# PY32F403xx register map
Vendor: PUYA Co.Ltd; Series: ARMCM4; File version: 1.2
CPU: CM4 r0p1, little endian, MPU, FPU, 4 interrupt priority bits
Registers are 32-bit, read-write, reset 0x0 unless marked. A register's access mark holds for its fields unless they carry their own. Offsets are from the block's base; [hi:lo] are bit positions; {n}, {i} and the like mark numbered series.

## TIM6 — desc TIM
Base 0x40001000
Same registers: TIM7 0x40001400
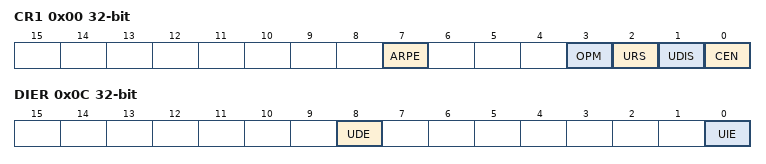
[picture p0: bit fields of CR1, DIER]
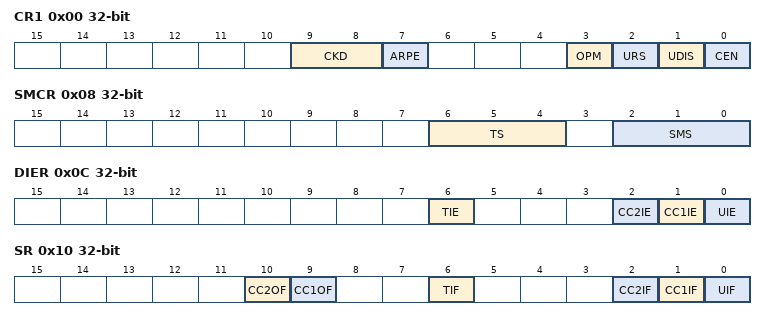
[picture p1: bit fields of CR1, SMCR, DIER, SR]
0x00 CR1
  [7] ARPE, [3] OPM, [2] URS, [1] UDIS, [0] CEN
0x04 CR2
  [6:4] MMS
    1=0; 2=1; 4=2
0x0C DIER
  [8] UDE, [0] UIE
0x10 SR
  [0] UIF
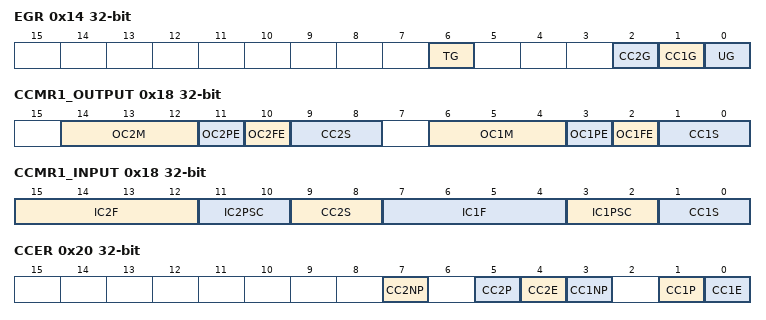
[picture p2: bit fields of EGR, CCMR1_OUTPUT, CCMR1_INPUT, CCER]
0x14 EGR
  [0] UG
0x24 CNT
  [15:0] CNT
0x28 PSC
  [15:0] PSC
0x2C ARR
  [15:0] ARR

## TIM9 — desc TIM
Base 0x40014C00
Same registers: TIM12 0x40001800
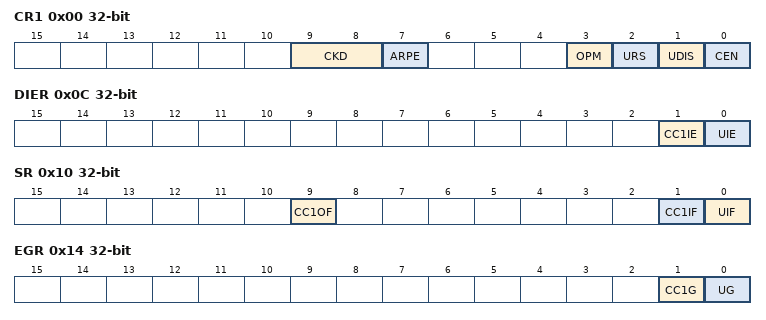
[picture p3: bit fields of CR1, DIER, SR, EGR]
0x00 CR1
  [9:8] CKD
    1=0; 2=1
  [7] ARPE
  [3] OPM
  [2] URS
  [1] UDIS
  [0] CEN
0x08 SMCR
  [6:4] TS
    1=0; 2=1; 4=2
  [2:0] SMS
    1=0; 2=1; 4=2
0x0C DIER
  [6] TIE, [2] CC2IE, [1] CC1IE, [0] UIE
0x10 SR
  [10] CC2OF, [9] CC1OF, [6] TIF, [2] CC2IF, [1] CC1IF, [0] UIF
0x14 EGR
  [6] TG, [2] CC2G, [1] CC1G, [0] UG
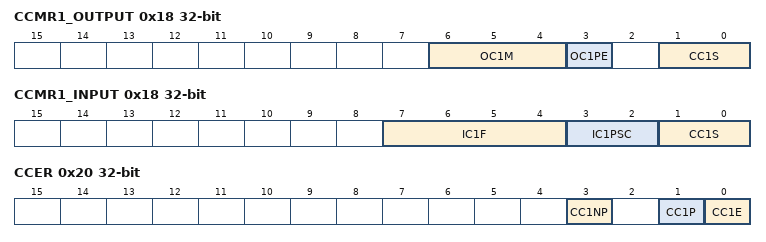
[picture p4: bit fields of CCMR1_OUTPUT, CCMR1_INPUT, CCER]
0x18 CCMR1_OUTPUT
  [14:12] OC2M, [11] OC2PE, [10] OC2FE, [9:8] CC2S, [6:4] OC1M, [3] OC1PE, [2] OC1FE, [1:0] CC1S
0x18 CCMR1_INPUT (alternate view of CCMR1_OUTPUT)
  [15:12] IC2F, [11:10] IC2PSC, [9:8] CC2S, [7:4] IC1F, [3:2] IC1PSC, [1:0] CC1S
0x20 CCER
  [7] CC2NP, [5] CC2P, [4] CC2E, [3] CC1NP, [1] CC1P, [0] CC1E
0x24 CNT
  [15:0] CNT
0x28 PSC
  [15:0] PSC
0x2C ARR
  [15:0] ARR
0x34 CCR1
  [15:0] CCR1
0x38 CCR2
  [15:0] CCR2

## TIM10 — desc TIM
Base 0x40015000
Same registers: TIM13 0x40001C00, TIM14 0x40002000, TIM11 0x40015400
0x00 CR1
  [9:8] CKD
    1=0; 2=1
  [7] ARPE
  [3] OPM
  [2] URS
  [1] UDIS
  [0] CEN
0x0C DIER
  [1] CC1IE, [0] UIE
0x10 SR
  [9] CC1OF, [1] CC1IF, [0] UIF
0x14 EGR
  [1] CC1G, [0] UG
0x18 CCMR1_OUTPUT
  [6:4] OC1M, [3] OC1PE, [1:0] CC1S
0x18 CCMR1_INPUT (alternate view of CCMR1_OUTPUT)
  [7:4] IC1F, [3:2] IC1PSC, [1:0] CC1S
0x20 CCER
  [3] CC1NP, [1] CC1P, [0] CC1E
0x24 CNT
  [15:0] CNT
0x28 PSC
  [15:0] PSC
0x2C ARR
  [15:0] ARR
0x34 CCR1
  [15:0] CCR1

## USART1 — desc USART
Base 0x40013800
Same registers: USART2 0x40004400, USART3 0x40004800, USART4 0x40004C00, USART5 0x40005000
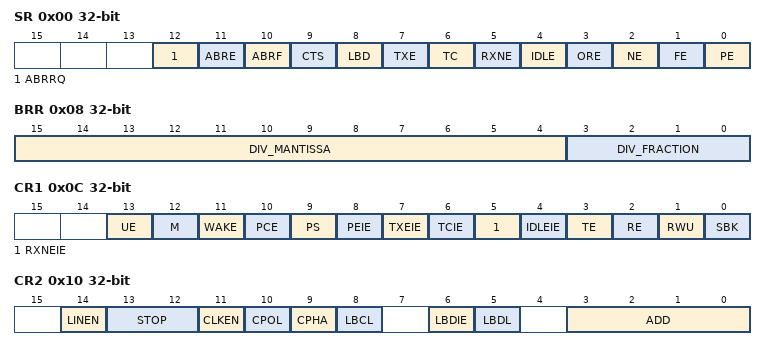
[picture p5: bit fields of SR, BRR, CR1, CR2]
0x00 SR
  [12] ABRRQ, [11] ABRE ro, [10] ABRF ro, [9] CTS, [8] LBD, [7] TXE ro, [6] TC, [5] RXNE, [4] IDLE ro, [3] ORE ro, [2] NE ro, [1] FE ro, [0] PE ro
0x04 DR
  [8:0] DR
0x08 BRR
  [15:4] DIV_MANTISSA
  [3:0] DIV_FRACTION
    1=0; 2=1; 4=2; 8=3
0x0C CR1
  [13] UE, [12] M, [11] WAKE, [10] PCE, [9] PS, [8] PEIE, [7] TXEIE, [6] TCIE, [5] RXNEIE, [4] IDLEIE, [3] TE, [2] RE, [1] RWU, [0] SBK
0x10 CR2
  [14] LINEN
  [13:12] STOP
    1=0; 2=1
  [11] CLKEN
  [10] CPOL
  [9] CPHA
  [8] LBCL
  [6] LBDIE
  [5] LBDL
  [3:0] ADD
    1=0; 2=1; 4=2; 8=3
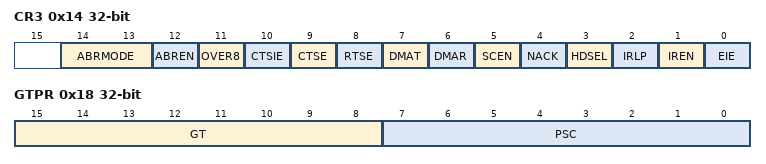
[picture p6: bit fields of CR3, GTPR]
0x14 CR3
  [14:13] ABRMODE, [12] ABREN, [11] OVER8, [10] CTSIE, [9] CTSE, [8] RTSE, [7] DMAT, [6] DMAR, [5] SCEN, [4] NACK, [3] HDSEL, [2] IRLP, [1] IREN, [0] EIE
0x18 GTPR
  [15:8] GT, [7:0] PSC

## USB
Base 0x40005C00
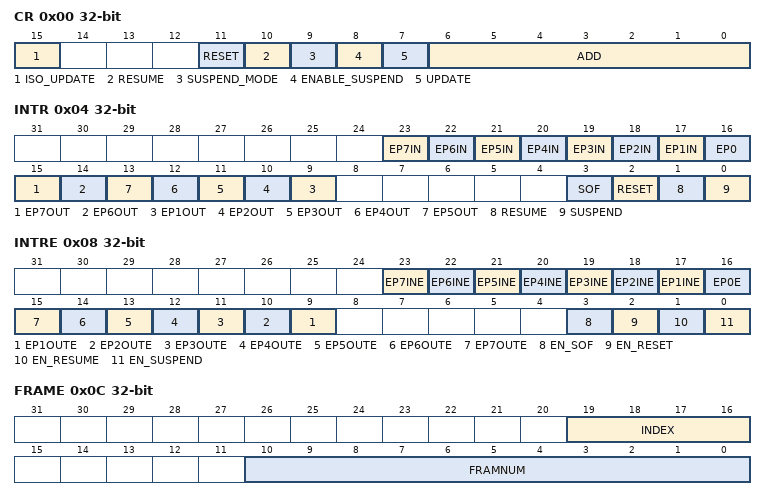
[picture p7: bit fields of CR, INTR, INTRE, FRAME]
0x00 CR
  [15] ISO_UPDATE, [11] RESET ro, [10] RESUME, [9] SUSPEND_MODE ro, [8] ENABLE_SUSPEND, [7] UPDATE ro, [6:0] ADD
0x04 INTR
  [n+16] EP{n}IN ro (n=1..7)
  [16] EP0 ro
  [15] EP7OUT ro — desc EP4OUT
  [14] EP6OUT ro — desc EP4OUT
  [n+8] EP{n}OUT ro (n=1..5)
  [3] SOF ro
  [2] RESET ro
  [1] RESUME ro
  [0] SUSPEND ro
0x08 INTRE
  [n+16] EP{n}INE (n=1..7), [16] EP0E, [n+8] EP{n}OUTE (n=1..7), [3] EN_SOF, [2] EN_RESET, [1] EN_RESUME, [0] EN_SUSPEND
0x0C FRAME
  [19:16] INDEX ro, [10:0] FRAMNUM ro
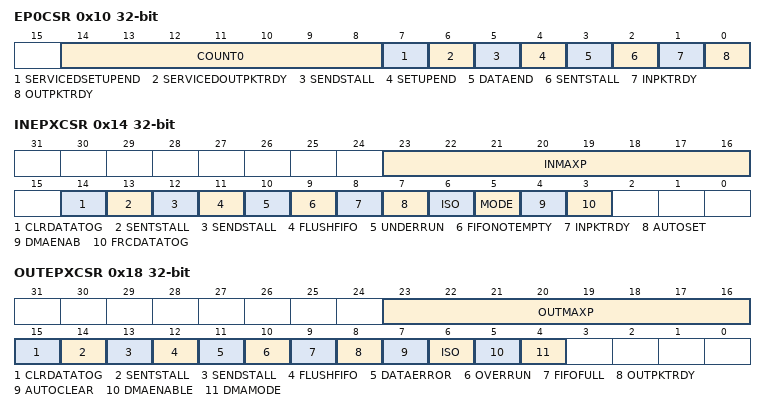
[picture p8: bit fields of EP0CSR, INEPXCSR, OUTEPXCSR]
0x10 EP0CSR
  [14:8] COUNT0 ro, [7] SERVICEDSETUPEND, [6] SERVICEDOUTPKTRDY, [5] SENDSTALL, [4] SETUPEND ro, [3] DATAEND, [2] SENTSTALL, [1] INPKTRDY, [0] OUTPKTRDY ro
0x14 INEPXCSR
  [23:16] INMAXP
  [14] CLRDATATOG
  [13] SENTSTALL
  [12] SENDSTALL
  [11] FLUSHFIFO
  [10] UNDERRUN ro
  [9] FIFONOTEMPTY
  [8] INPKTRDY — des INPKTRDY
  [7] AUTOSET — des AUTOSET
  [6] ISO
  [5] MODE
  [4] DMAENAB
  [3] FRCDATATOG
0x18 OUTEPXCSR
  [23:16] OUTMAXP, [15] CLRDATATOG, [14] SENTSTALL, [13] SENDSTALL, [12] FLUSHFIFO, [11] DATAERROR ro, [10] OVERRUN, [9] FIFOFULL ro, [8] OUTPKTRDY, [7] AUTOCLEAR, [6] ISO, [5] DMAENABLE, [4] DMAMODE
0x1C OUTCOUNT
  [9:0] OUTCOUNT ro

## WWDG
Base 0x40002C00
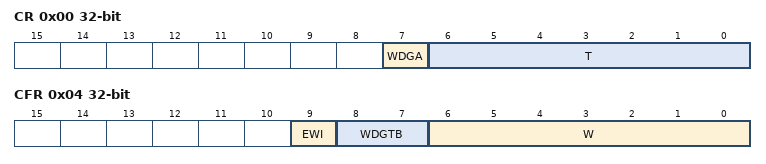
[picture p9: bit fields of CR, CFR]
0x00 CR
  [7] WDGA
  [6:0] T
    1=0; 2=1; 4=2; 8=3; 16=4; 32=5; 64=6
0x04 CFR
  [9] EWI
  [8:7] WDGTB
    1=0; 2=1
  [6:0] W
    1=0; 2=1; 4=2; 8=3; 16=4; 32=5; 64=6
0x08 SR
  [0] EWIF
